# MM32F103xx register map
File version: 1.08
Registers are 32-bit, read-write, reset 0x0 unless marked. A register's access mark holds for its fields unless they carry their own. Offsets are from the block's base; [hi:lo] are bit positions; {n}, {i} and the like mark numbered series.

## UART1 — Universal asynchronous receiver transmitter
Base 0x40013800
Same registers: UART2 0x40004400, UART3 0x40004800
0x00 TDR — Transmit data register
  [7:0] TXREG
0x04 RDR ro — Receive data register
  [7:0] RXREG
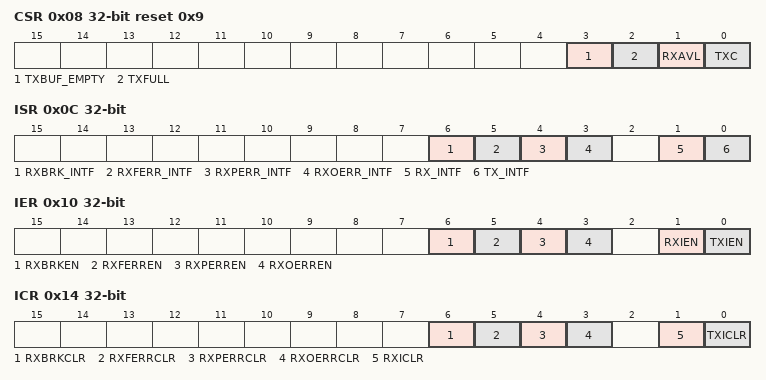
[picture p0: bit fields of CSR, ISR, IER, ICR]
0x08 CSR ro reset 0x9 — Current status register
  [3] TXBUF_EMPTY — Transmit buffer empty flag bit
  [2] TXFULL — Transmit buffer full flag bit
  [1] RXAVL — Receive valid data flag bit
  [0] TXC — Transmit complete flag bit
0x0C ISR ro — Interrupt status register
  [6] RXBRK_INTF — Receive frame break interrupt flag bit
  [5] RXFERR_INTF — Frame error interrupt flag bit
  [4] RXPERR_INTF — Parity error interrupt flag bit
  [3] RXOERR_INTF — Receive overflow error interrupt flag bit
  [1] RX_INTF — Receive valid data interrupt flag bit
  [0] TX_INTF — Transmit buffer empty interrupt flag bit
0x10 IER — Interrupt enable register
  [6] RXBRKEN — Receive frame break interrupt enable bit
  [5] RXFERREN — Frame error interrupt enable bit
  [4] RXPERREN — Parity error interrupt enable bit
  [3] RXOERREN — Receive overflow error interrupt enable bit
  [1] RXIEN — Receive buffer interrupt enable bit
  [0] TXIEN — Transmit buffer empty interrupt enable bit
0x14 ICR wo
  [6] RXBRKCLR — Receive frame break interrupt clear bit
  [5] RXFERRCLR — Frame error interrupt clear bit
  [4] RXPERRCLR — Parity error interrupt clear bit
  [3] RXOERRCLR — Receive overflow error interrupt clear bit
  [1] RXICLR — Receive interrupt clear bit
  [0] TXICLR — Transmit buffer empty interrupt clear bit
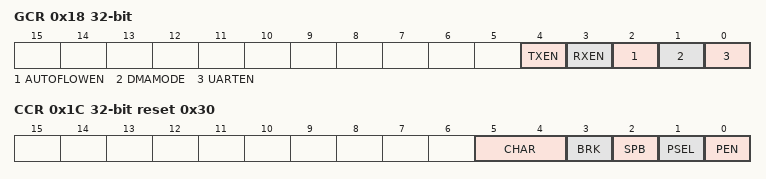
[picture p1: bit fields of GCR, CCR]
0x18 GCR — Global control register
  [4] TXEN — Enable transmit
  [3] RXEN — Enable receive
  [2] AUTOFLOWEN — Automatic flow control enable bit
  [1] DMAMODE — DMA mode selection bit
  [0] UARTEN — UART mode selection bit
0x1C CCR reset 0x30 — common control register
  [5:4] CHAR — UART width bit
  [3] BRK — UART transmit frame break
  [2] SPB — Stop bit selection
  [1] PSEL — Parity selection bit
  [0] PEN — Parity enable bit
0x20 BRR reset 0x1 — Baud rate register
  [15:0] DIV_MANTISSA — Mantissa part of UARTDIV
0x24 FRA — Fractional baud rate register
  [3:0] DIV_Fraction — Fractional part of UARTDIV

## USB — Universal serial bus full-speed device interface
Base 0x40005C00
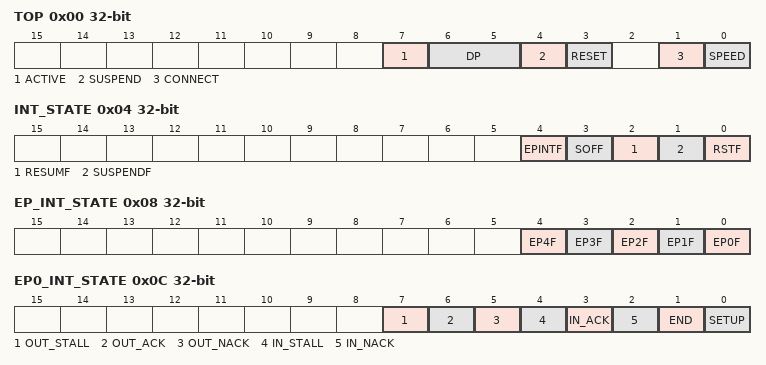
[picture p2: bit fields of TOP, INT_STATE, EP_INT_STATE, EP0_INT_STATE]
0x00 TOP
  [7] ACTIVE — USB bus is active
  [6:5] DP — Current USB DP/DM line state
  [4] SUSPEND — USB suspend state
  [3] RESET — Reset EP and FIFO in USB controller
  [1] CONNECT — USB connection
  [0] SPEED
0x04 INT_STATE ro
  [4] EPINTF — EP interrupt received
  [3] SOFF — BUS received
  [2] RESUMF — BUS resume received
  [1] SUSPENDF — BUS suspend received
  [0] RSTF — BUS reset received
0x08 EP_INT_STATE ro
  [n] EP{n}F (n=0..4) — EP{n} interrupt received
0x0C EP0_INT_STATE ro
  [7] OUT_STALL — OUT-STALL received
  [6] OUT_ACK — OUT-ACK received
  [5] OUT_NACK — OUT-NACK received
  [4] IN_STALL — IN-STALL received
  [3] IN_ACK — IN-ACK received
  [2] IN_NACK — IN-NACK received
  [1] END — Status stage finished
  [0] SETUP — SETUP packet received
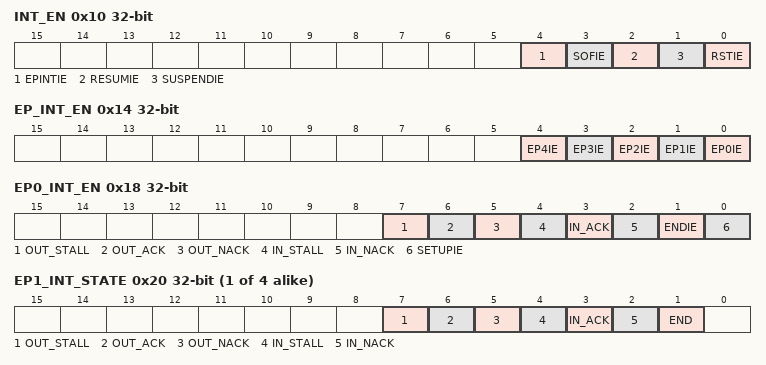
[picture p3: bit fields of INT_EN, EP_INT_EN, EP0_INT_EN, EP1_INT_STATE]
0x10 INT_EN
  [4] EPINTIE — EP interrupt enable
  [3] SOFIE — SOF interrupt enable
  [2] RESUMIE — BUS resume interrupt enable
  [1] SUSPENDIE — BUS suspend interrupt enable
  [0] RSTIE — BUS reset interrupt enable
0x14 EP_INT_EN
  [n] EP{n}IE (n=0..4) — EP{n} interrupt enable
0x18 EP0_INT_EN
  [7] OUT_STALL — OUT-STALL interrupt enable
  [6] OUT_ACK — OUT-ACK interrupt enable
  [5] OUT_NACK — OUT-NACK interrupt enable
  [4] IN_STALL — IN-STALL interrupt enable
  [3] IN_ACK — IN-ACK interrupt enable
  [2] IN_NACK — IN-NACK interrupt enable
  [1] ENDIE — Status stage finished interrupt enable
  [0] SETUPIE — SETUP packet interrupt enable
{0x1C+4i} EP{i}_INT_STATE (i=1..4)
  [7] OUT_STALL — OUT-STALL received
  [6] OUT_ACK — OUT-ACK received
  [5] OUT_NACK — OUT-NACK received
  [4] IN_STALL — IN-STALL received
  [3] IN_ACK — IN-ACK received
  [2] IN_NACK — IN-NACK received
  [1] END — Transfer finished
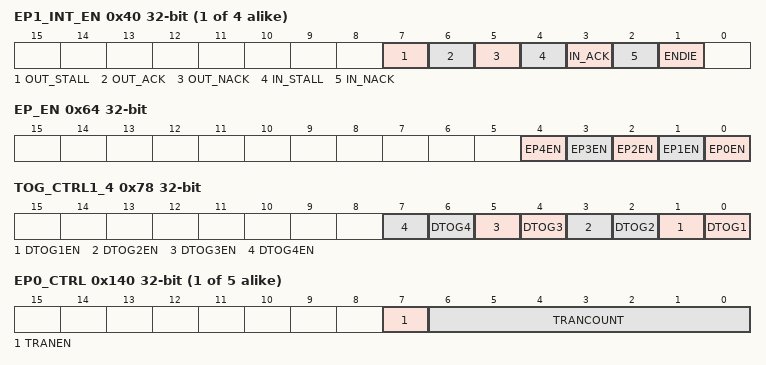
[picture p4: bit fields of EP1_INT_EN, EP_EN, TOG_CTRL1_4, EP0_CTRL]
{0x3C+4i} EP{i}_INT_EN (i=1..4)
  [7] OUT_STALL — OUT-STALL interrupt enable
  [6] OUT_ACK — OUT-ACK interrupt enable
  [5] OUT_NACK — OUT-NACK interrupt enable
  [4] IN_STALL — IN-STALL interrupt enable
  [3] IN_ACK — IN-ACK interrupt enable
  [2] IN_NACK — IN-NACK interrupt enable
  [1] ENDIE — Finished interrupt enable
0x60 ADDR
  [6:0] ADDR — USB address
0x64 EP_EN
  [n] EP{n}EN (n=0..4) — Enable End Point {n}
0x78 TOG_CTRL1_4
  [2n-1] DTOG{n}EN (n=1..4) — Set End Point {n} enable
  [2n-2] DTOG{n} (n=1..4) — Set End Point {n} Toggle
{0x80+4i} SETUP{i} ro (i=0..7)
  [7:0] SETUPD{i} — Setup Data {i}
0xA0 PACKET_SIZE reset 0x40
  [7:0] SIZE0 — USB DMA Max Packet Size
{0x100+4i} EP{i}_AVAIL ro (i=0..4)
  [7:0] EP{i}AVIL — EP{i} FIFO available data number
{0x140+4i} EP{i}_CTRL (i=0..4)
  [7] TRANEN — EP{i} transfer enable
  [6:0] TRANCOUNT — EP{i} transfer counter
{0x160+4i} EP{i}_FIFO (i=0..4)
  [7:0] EP{i}_FIFO — EP{i} FIFO port
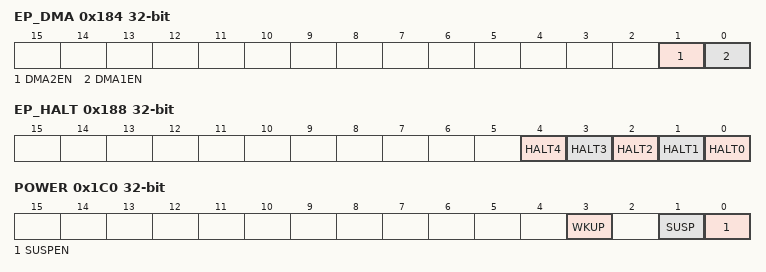
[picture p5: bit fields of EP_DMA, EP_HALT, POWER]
0x184 EP_DMA
  [1] DMA2EN — EP2 DMA enable
  [0] DMA1EN — EP1 DMA enable
0x188 EP_HALT
  [n] HALT{n} (n=0..4) — EP{n} halt
0x1C0 POWER
  [3] WKUP — Enable controller wake up from suspend state
  [1] SUSP — suspend
  [0] SUSPEN — BUS suspend enable bit

## WWDG — Window watchdog
Base 0x40002C00
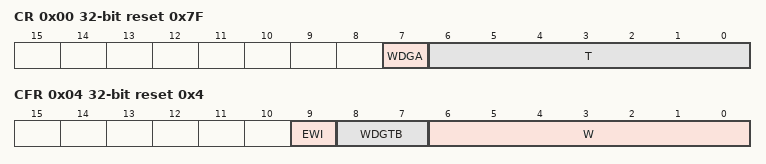
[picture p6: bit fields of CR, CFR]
0x00 CR reset 0x7F — Control register
  [7] WDGA — Activation bit
  [6:0] T — 7-bit counter
0x04 CFR reset 0x4 — Configuration register
  [9] EWI — Early wakeup interrupt
  [8:7] WDGTB — Timer base
  [6:0] W — 7-bit window value
0x08 SR ro — Status register
  [0] EWIF — Early wakeup interrupt flag
